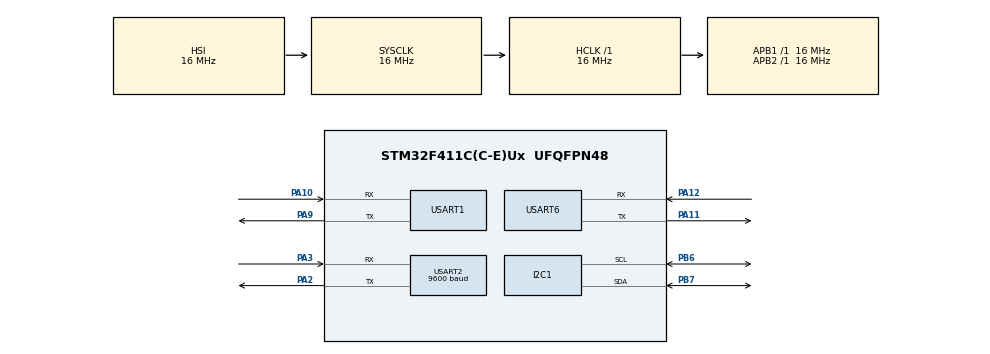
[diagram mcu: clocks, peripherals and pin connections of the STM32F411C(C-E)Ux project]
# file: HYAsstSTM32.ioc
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I2C1.I2C_Mode=I2C_Fast
Mcu.Family=STM32F4
Mcu.Name=STM32F411C(C-E)Ux
Mcu.Package=UFQFPN48
NVIC.PriorityGroup=NVIC_PRIORITYGROUP_4
NVIC.USART1_IRQn=true\:0\:0\:false\:false\:true\:true\:true
NVIC.USART2_IRQn=true\:0\:0\:false\:false\:true\:true\:true
NVIC.USART6_IRQn=true\:0\:0\:false\:false\:true\:true\:true
PA10.Mode=Asynchronous
PA10.Signal=USART1_RX
PA11.Mode=Asynchronous
PA11.Signal=USART6_TX
PA12.Mode=Asynchronous
PA12.Signal=USART6_RX
PA2.Mode=Asynchronous
PA2.Signal=USART2_TX
PA3.Mode=Asynchronous
PA3.Signal=USART2_RX
PA9.Mode=Asynchronous
PA9.Signal=USART1_TX
PB6.Mode=I2C
PB6.Signal=I2C1_SCL
PB7.Mode=I2C
PB7.Signal=I2C1_SDA
ProjectManager.HeapSize=0x200
ProjectManager.StackSize=0x400
ProjectManager.TargetToolchain=STM32CubeIDE
RCC.AHBFreq_Value=16000000
RCC.APB1Freq_Value=16000000
RCC.APB2Freq_Value=16000000
RCC.CortexFreq_Value=16000000
RCC.HSE_VALUE=25000000
RCC.HSI_VALUE=16000000
RCC.LSE_VALUE=32768
RCC.SYSCLKFreq_VALUE=16000000
RCC.VCOOutputFreq_Value=192000000
USART1.VirtualMode=VM_ASYNC
USART2.BaudRate=9600
USART2.VirtualMode=VM_ASYNC
USART6.VirtualMode=VM_ASYNC
board=custom

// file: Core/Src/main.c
/**
  ******************************************************************************
  * @file           : main.c
  * @brief          : Main program body
  ******************************************************************************
  * @attention designed for STM32F411CEU6
  ******************************************************************************
  */

#define SerialDebug
//#define SerialGPSdebug
//#define SerialDebugFloatTest

#include "main.h"
#include <stdio.h>
#include "LED_Functions/LED_OUTPUT.h"
#include "GPS_Decoder/GPSdecode.h"
#include "MPU6050/Accident_Alert.h"
#include "MQTT/general_command.h"
#include "MQTT/MQTT.h"

void SystemClock_Config(void);
static void MX_GPIO_Init(void);
static void MX_I2C1_Init(void);
static void MX_USART2_UART_Init(void);
static void MX_USART6_UART_Init(void);
static void MX_USART1_UART_Init(void);

// Serial output for Debug @ HUART1
#ifdef __GNUC__
#define PUTCHAR_PROTOTYPE int __io_putchar(int ch)
#else
#define PUTCHAR_PROTOTYPE int fputc(int ch, FILE *f)
#endif

PUTCHAR_PROTOTYPE {
	HAL_UART_Transmit((UART_HandleTypeDef *)&huart1, (uint8_t*)&ch, 1, 0xFFFF);
	return ch;
}

// GPS decoder

#define GPS_Delay_Time 1000
uint8_t                gps_init;
uint8_t                gps_uart[5000];
nmea_slmsg             NMEAslmsg;
nmea_utc_time          NMEAutctime;
nmea_msg           	   NMEAmsg;
gps_data               NMEAdata;
dataPoints             DP;

int GPS_decode (void) {

	HAL_UART_Receive(&huart2, gps_uart, sizeof(gps_uart), GPS_Delay_Time);

	#ifdef SerialGPSdebug
		//printf("USART data:\r\n%s\r\n", gps_uart);
	#endif

	NMEA_GPGGA_Analysis (&NMEAmsg, (uint8_t*) gps_uart);

	if (!NMEAmsg.gpssta) {
		LED_GPSRFS_ON();
		#ifdef SerialDebug
			printf("** GPS NO SIGNAL **\r\n");
		#endif
		return 1;
	} else {
		LED_GPSRFS_ON();
		NMEA_GPRMC_Analysis (&NMEAmsg, (uint8_t*) gps_uart);
		NMEA_GPGSA_Analysis (&NMEAmsg, (uint8_t*) gps_uart);
		NMEA_GPVTG_Analysis (&NMEAmsg, (uint8_t*) gps_uart);
		NMEA_GPRMC_Analysis (&NMEAmsg, (uint8_t*) gps_uart);

		NMEA_GPS_DATA_PHRASE(&NMEAmsg, &NMEAdata);

		DP.latitude  = NMEAdata.latitude;
		DP.longitude = NMEAdata.longitude;
		DP.speed     = NMEAdata.speed;
		DP.pdop      = NMEAdata.pdop;

		#ifdef SerialGPSDebug
			printf("\r\n** GPS Serial Debug **\r\n");
			printf("GPS status: %s, PDOT: %f\r\n", NMEAmsg.gpssta^2? "3D":"2D", NMEAdata.pdop);
			printf("UTC time: %02d:%02d:%02d\r\n", NMEAmsg.utc.hour, NMEAmsg.utc.min, NMEAmsg.utc.sec);
			printf("Lat: %.6f, Log: %.6f, Spd: %.6f\r\n", NMEAdata.latitude, NMEAdata.longitude, NMEAdata.speed);
		#endif

		LED_GPSRFS_OFF();
		return 0;
	}
}

#undef GPS_Delay_Time

// main

signed main(void) {

	HAL_Init();

	SystemClock_Config();

	MX_GPIO_Init();
	MX_I2C1_Init();
	MX_USART2_UART_Init();
	MX_USART6_UART_Init();
	MX_USART1_UART_Init();

	accidentMonitorSetup();

	LED_OUTPUT_INIT();
	LED_PC13_INIT();

	LED_OUTPUT_TEST();

	HAL_UART_Receive_IT(&huart2, &gps_init, 1);

	#ifdef SerialDebugFloatTest
		printf("initialization success.\r\n");
		register float nnnnn = 114.514;
		printf("\r\nFLOAT TEST\r\n%f\r\n", nnnnn);
		nnnnn = 1919.810;
		printf("%f\r\n\r\n", nnnnn);
	#endif

	register int ifGpsReady = 0;
	//LED_DATUPD_ON(); LED_ALERT_ON();
	LED_GPSRFS_ON(); LED_DATUPD_ON();

	while (!ifGpsReady || (SIM7020_state^2)) {
		if (!ifGpsReady && !Query_Signal_Quality()) {
			ifGpsReady = 1; LED_GPSRFS_OFF();
		} if (SIM7020_state^2) {
			ONENET_MQTT(&DP); printf("SIM7020Searching..\r\n");
		} else LED_DATUPD_OFF();
		printf("GPS searching signal...\r\n"); HAL_Delay(1000);
	}

	/*
	while (Query_Signal_Quality()) {
		printf("Searching Signal...\r\n");
		HAL_Delay(1000);
	} printf("Signal Success.\r\n");
	*/

	LED_ALERT_OFF();

	int GPSsta;
	while (1) {
		GPSsta = GPS_decode();
		DP.flag = accidentJudge(&NMEAdata);
		if (!GPSsta) ONENET_MQTT(&DP);
	}
}

void SystemClock_Config(void) {
  RCC_OscInitTypeDef RCC_OscInitStruct = {0};
	RCC_ClkInitTypeDef RCC_ClkInitStruct = {0};

	/** Configure the main internal regulator output voltage
	*/
	__HAL_RCC_PWR_CLK_ENABLE();
	__HAL_PWR_VOLTAGESCALING_CONFIG(PWR_REGULATOR_VOLTAGE_SCALE1);
	/** Initializes the RCC Oscillators according to the specified parameters
	* in the RCC_OscInitTypeDef structure.
	*/
	RCC_OscInitStruct.OscillatorType = RCC_OSCILLATORTYPE_HSI;
	RCC_OscInitStruct.HSIState = RCC_HSI_ON;
	RCC_OscInitStruct.HSICalibrationValue = RCC_HSICALIBRATION_DEFAULT;
	RCC_OscInitStruct.PLL.PLLState = RCC_PLL_NONE;
	if (HAL_RCC_OscConfig(&RCC_OscInitStruct) != HAL_OK) {
		Error_Handler();
	}
	/** Initializes the CPU, AHB and APB buses clocks
	*/
	RCC_ClkInitStruct.ClockType = RCC_CLOCKTYPE_HCLK|RCC_CLOCKTYPE_SYSCLK
															|RCC_CLOCKTYPE_PCLK1|RCC_CLOCKTYPE_PCLK2;
	RCC_ClkInitStruct.SYSCLKSource = RCC_SYSCLKSOURCE_HSI;
	RCC_ClkInitStruct.AHBCLKDivider = RCC_SYSCLK_DIV1;
	RCC_ClkInitStruct.APB1CLKDivider = RCC_HCLK_DIV1;
	RCC_ClkInitStruct.APB2CLKDivider = RCC_HCLK_DIV1;

	if (HAL_RCC_ClockConfig(&RCC_ClkInitStruct, FLASH_LATENCY_0) != HAL_OK) {
		Error_Handler();
	}
}

static void MX_I2C1_Init(void) {

	hi2c1.Instance = I2C1;
	hi2c1.Init.ClockSpeed = 400000;
	hi2c1.Init.DutyCycle = I2C_DUTYCYCLE_2;
	hi2c1.Init.OwnAddress1 = 0;
	hi2c1.Init.AddressingMode = I2C_ADDRESSINGMODE_7BIT;
	hi2c1.Init.DualAddressMode = I2C_DUALADDRESS_DISABLE;
	hi2c1.Init.OwnAddress2 = 0;
	hi2c1.Init.GeneralCallMode = I2C_GENERALCALL_DISABLE;
	hi2c1.Init.NoStretchMode = I2C_NOSTRETCH_DISABLE;
	if (HAL_I2C_Init(&hi2c1) != HAL_OK) {
		Error_Handler();
	}

}

static void MX_USART1_UART_Init(void) {

	huart1.Instance = USART1;
	huart1.Init.BaudRate = 115200;
	huart1.Init.WordLength = UART_WORDLENGTH_8B;
	huart1.Init.StopBits = UART_STOPBITS_1;
	huart1.Init.Parity = UART_PARITY_NONE;
	huart1.Init.Mode = UART_MODE_TX_RX;
	huart1.Init.HwFlowCtl = UART_HWCONTROL_NONE;
	huart1.Init.OverSampling = UART_OVERSAMPLING_16;
	if (HAL_UART_Init(&huart1) != HAL_OK)
	{
		Error_Handler();
	}

}

static void MX_USART2_UART_Init(void) {

	huart2.Instance = USART2;
	huart2.Init.BaudRate = 9600;
	huart2.Init.WordLength = UART_WORDLENGTH_8B;
	huart2.Init.StopBits = UART_STOPBITS_1;
	huart2.Init.Parity = UART_PARITY_NONE;
	huart2.Init.Mode = UART_MODE_TX_RX;
	huart2.Init.HwFlowCtl = UART_HWCONTROL_NONE;
	huart2.Init.OverSampling = UART_OVERSAMPLING_16;
	if (HAL_UART_Init(&huart2) != HAL_OK) {
		Error_Handler();
	}

}

static void MX_USART6_UART_Init(void) {

	huart6.Instance = USART6;
	huart6.Init.BaudRate = 115200;
	huart6.Init.WordLength = UART_WORDLENGTH_8B;
	huart6.Init.StopBits = UART_STOPBITS_1;
	huart6.Init.Parity = UART_PARITY_NONE;
	huart6.Init.Mode = UART_MODE_TX_RX;
	huart6.Init.HwFlowCtl = UART_HWCONTROL_NONE;
	huart6.Init.OverSampling = UART_OVERSAMPLING_16;
	if (HAL_UART_Init(&huart6) != HAL_OK) {
		Error_Handler();
	}

}

static void MX_GPIO_Init(void) {

	/* GPIO Ports Clock Enable */
	__HAL_RCC_GPIOA_CLK_ENABLE();
	__HAL_RCC_GPIOB_CLK_ENABLE();

}

void Error_Handler(void) {
	/* USER CODE BEGIN Error_Handler_Debug */
	/* User can add his own implementation to report the HAL error return state */
	__disable_irq();
	while (1) {
		LED_PC13_BLINK(1000);
	}
	/* USER CODE END Error_Handler_Debug */
}

/************************ (C) COPYRIGHT STMicroelectronics *****END OF FILE****/
